# CONTROLSS_GLOBAL_CTRL_CONTROLSS_CTRL_502F0000h register map
Vendor: Texas Instruments
Peripheral module from a debugger description file (folder AM263X).
Registers are 32-bit, read-write, reset 0x0 unless marked. A register's access mark holds for its fields unless they carry their own. Offsets are as the file gives them; lines under a group give offsets from that group; [hi:lo] are bit positions; {n}, {i} and the like mark numbered series; 'fields as' and 'values as' point back to an identical list; <NAME> marks a mode.

## CONTROLSS_CTRL
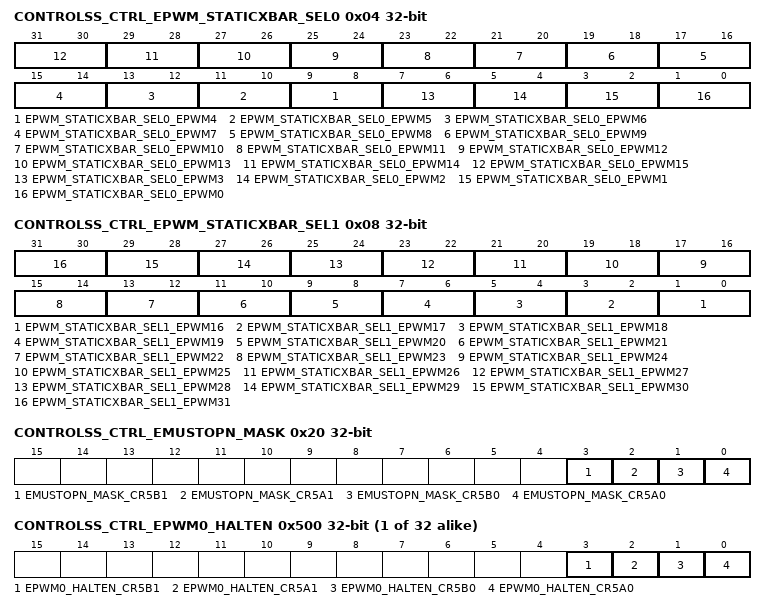
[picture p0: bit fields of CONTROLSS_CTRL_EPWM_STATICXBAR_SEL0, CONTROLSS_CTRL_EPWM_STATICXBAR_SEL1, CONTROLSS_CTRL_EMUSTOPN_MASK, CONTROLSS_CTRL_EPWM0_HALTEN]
0x04 CONTROLSS_CTRL_EPWM_STATICXBAR_SEL0 — Static crossbar for epwm select.
  [2n+1:2n] EPWM_STATICXBAR_SEL0_EPWM{n} (n=4..15) — EPWM{n} access from PCR grouping. Write the following value to access groups - - 2'b00 = G0, 2'b01 =G1, 2'b10 =G2, 2'b11 =G3
  [7:6] EPWM_STATICXBAR_SEL0_EPWM3 — EPWM3 access from PCR grouping. Write the following value to access groups - 2'b00 = G0, 2'b01 =G1, 2'b10 =G2, 2'b11 =G3
  [5:4] EPWM_STATICXBAR_SEL0_EPWM2 — EPWM2 access from PCR grouping. Write the following value to access groups - - 2'b00 = G0, 2'b01 =G1, 2'b10 =G2, 2'b11 =G3
  [3:2] EPWM_STATICXBAR_SEL0_EPWM1 — EPWM1 access from PCR grouping. Write the following value to access groups - - 2'b00 = G0, 2'b01 =G1, 2'b10 =G2, 2'b11 =G3
  [1:0] EPWM_STATICXBAR_SEL0_EPWM0 — EPWM0 access from PCR grouping. Write the following value to access groups - - 2'b00 = G0, 2'b01 =G1, 2'b10 =G2, 2'b11 =G3
0x08 CONTROLSS_CTRL_EPWM_STATICXBAR_SEL1 — Static crossbar for epwm select.
  [2n-31:2n-32] EPWM_STATICXBAR_SEL1_EPWM{n} (n=16..31) — EPWM{n} access from PCR grouping. Write the following value to access groups - - 2'b00 = G0, 2'b01 =G1, 2'b10 =G2, 2'b11 =G3
0x10 CONTROLSS_CTRL_EPWM_CLKSYNC — Epwm clock sync.
  [31:0] EPWM_CLKSYNC_BIT — EPWM clock sync for each EPWM instance. Set the bit corresponding to the instance number to enable that EPWM instance. When set, all enabled EPWM module clocks are started with the first rising edge of TBCLK aligned.Refer to TRM for more details.Writing 1'b1 will allow to enable corresponding EPWM instanceWriting 1'b0 will disable corresponding EPWM instance.
0x18 CONTROLSS_CTRL_SDFM1_CLK0_SEL — Sdfm1 clock select.
  [0] SDFM1_CLK0_SEL_SEL — SDFM1 clock CK0 selectWrite 1'b0: source is SDFM1 CK0 from PinmuxWrite 1'b1: source is SDFM0 CK0 from Pinmux
0x20 CONTROLSS_CTRL_EMUSTOPN_MASK — Bit-mask for debug suspend cpu cores to EPWM.
  [3] EMUSTOPN_MASK_CR5B1 — Bit-mask for debug suspend cpu cores to EPWM1'b0 : R5FSS1_CORE1 enabled to control EMUSTOPn1'b1 : R5FSS1_CORE1 disabled to control EMUSTOPn
  [2] EMUSTOPN_MASK_CR5A1 — Bit-mask for debug suspend cpu cores to EPWM1'b0 : R5FSS1_CORE0 enabled to control EMUSTOPn1'b1 : R5FSS1_CORE0 disabled to control EMUSTOPn
  [1] EMUSTOPN_MASK_CR5B0 — Bit-mask for debug suspend cpu cores to EPWM1'b0 : R5FSS0_CORE1 enabled to control EMUSTOPn1'b1 : R5FSS0_CORE1 disabled to control EMUSTOPn
  [0] EMUSTOPN_MASK_CR5A0 — Bit-mask for debug suspend cpu cores to EPWM1'b0 : R5FSS0_CORE0 enabled to control EMUSTOPn1'b1 : R5FSS0_CORE0 disabled to control EMUSTOPn
0x28 CONTROLSS_CTRL_CLB_AQ_EN0 — clb_aq_en0.
  [31:0] CLB_AQ_EN0_ENABLE — Enable ICCS control to CLB_AQ signal of PWM[15:0]. Set Bitx to 1'b1 to enable it for PWMx. Here x varies from 0-15.
0x30 CONTROLSS_CTRL_CLB_AQ_EN1 — clb_aq_en1.
  [31:0] CLB_AQ_EN1_ENABLE — Enable ICCS control to CLB_AQ signal of PWM[31:16].Set Bitx to 1'b1 to enable it for PWMx. Here x varies from 16-31.
0x38 CONTROLSS_CTRL_CLB_DB_EN0 — clb_db_en0.
  [31:0] CLB_DB_EN0_ENABLE — Enable ICCS control to CLB_DB signal of PWM[15:0]. Set Bitx to 1'b1 to enable it for PWMx. Here x varies from 0-15.
0x40 CONTROLSS_CTRL_CLB_DB_EN1 — clb_db_en1.
  [31:0] CLB_DB_EN1_ENABLE — Enable ICCS control to CLB_DB signal of PWM[31:16].Set Bitx to 1'b1 to enable it for PWMx. Here x varies from 16-31.
{0x100+4i} CONTROLSS_CTRL_EPWM{i}_CLK_GATE (i=0..31) — To clock gate epwm[x].
  [2:0] EPWM{i}_CLK_GATE_CLK_GATE — Writing 3'b111 will gate clock for corresponding epwm
{0x180+4i} CONTROLSS_CTRL_FSI_TX{i}_CLK_GATE (i=0..3) — fsi_tx[x] clock gate.
  [2:0] FSI_TX{i}_CLK_GATE_CLK_GATE — Writing 3'b111 will gate clock for corresponding fsi_tx
{0x190+4i} CONTROLSS_CTRL_FSI_RX{i}_CLK_GATE (i=0..3) — fsi_rx[x] clock gate.
  [2:0] FSI_RX{i}_CLK_GATE_CLK_GATE — Writing 3'b111 will gate clock for corresponding fsi_rx
{0x1A0+4i} CONTROLSS_CTRL_CMPSSA{i}_CLK_GATE (i=0..9) — cmpssa[x] clock gate.
  [2:0] CMPSSA{i}_CLK_GATE_CLK_GATE — Writing 3'b111 will gate clock for corresponding cmpssa
{0x1D0+4i} CONTROLSS_CTRL_CMPSSB{i}_CLK_GATE (i=0..9) — cmpssb[x] clock gate.
  [2:0] CMPSSB{i}_CLK_GATE_CLK_GATE — Writing 3'b111 will gate clock for corresponding cmpssb
{0x200+4i} CONTROLSS_CTRL_ECAP{i}_CLK_GATE (i=0..9) — Ecap[x] clock gate.
  [2:0] ECAP{i}_CLK_GATE_CLK_GATE — Writing 3'b111 will gate clock for corresponding ecap
{0x240+4i} CONTROLSS_CTRL_EQEP{i}_CLK_GATE (i=0..2) — Eqep[x] clock gate.
  [2:0] EQEP{i}_CLK_GATE_CLK_GATE — Writing 3'b111 will gate clock for corresponding eqep
0x250 CONTROLSS_CTRL_SDFM0_CLK_GATE — Sdfm[x] clock gate.
  [2:0] SDFM0_CLK_GATE_CLK_GATE — Writing 3'b111 will gate clock for corresponding sdfm
0x254 CONTROLSS_CTRL_SDFM1_CLK_GATE — Sdfm[x] clock gate.
  [2:0] SDFM1_CLK_GATE_CLK_GATE — Writing 3'b111 will gate clock for corresponding sdfm
0x258 CONTROLSS_CTRL_DAC_CLK_GATE — dac clock gate.
  [2:0] DAC_CLK_GATE_CLK_GATE — Writing 3'b111 will gate clock for dac
{0x25C+4i} CONTROLSS_CTRL_ADC{i}_CLK_GATE (i=0..4) — Adc[x] clock gate.
  [2:0] ADC{i}_CLK_GATE_CLK_GATE — Writing 3'b111 will gate clock for corresponding adc
{0x270+4i} CONTROLSS_CTRL_OTTO{i}_CLK_GATE (i=0..3) — Otto[x] clock gate.
  [2:0] OTTO{i}_CLK_GATE_CLK_GATE — Writing 3'b111 will gate clock for corresponding otto
0x280 CONTROLSS_CTRL_SDFM0_PLL_CLK_GATE — Sdfm[x]_pll clock gate.
  [2:0] SDFM0_PLL_CLK_GATE_CLK_GATE — Writing 3'b111 will gate clock for corresponding sdfm pll clock
0x284 CONTROLSS_CTRL_SDFM1_PLL_CLK_GATE — Sdfm[x]_pll clock gate.
  [2:0] SDFM1_PLL_CLK_GATE_CLK_GATE — Writing 3'b111 will gate clock for corresponding sdfm pll clock
{0x288+4i} CONTROLSS_CTRL_FSI_TX{i}_PLL_CLK_GATE (i=0..3) — fsi_tx[x]_pll clock gate.
  [2:0] FSI_TX{i}_PLL_CLK_GATE_CLK_GATE — Writing 3'b111 will gate clock for corresponding fsi rx pll clock
{0x300+4i} CONTROLSS_CTRL_EPWM{i}_RST (i=0..31) — Epwm[x]_reset.
  [2:0] EPWM{i}_RST_RST — Writing 3'b111 will generate reset for corresponding epwm
{0x380+4i} CONTROLSS_CTRL_FSI_TX{i}_RST (i=0..3) — fsi_tx[x]_reset.
  [2:0] FSI_TX{i}_RST_RST — Writing 3'b111 will generate reset for corresponding fsi_tx
{0x390+4i} CONTROLSS_CTRL_FSI_RX{i}_RST (i=0..3) — fsi_rx[x]_reset.
  [2:0] FSI_RX{i}_RST_RST — Writing 3'b111 will generate reset for corresponding fsi_rx
{0x3A0+4i} CONTROLSS_CTRL_CMPSSA{i}_RST (i=0..9) — cmpssa[x]_reset.
  [2:0] CMPSSA{i}_RST_RST — Writing 3'b111 will generate reset for corresponding cmpssa
{0x3D0+4i} CONTROLSS_CTRL_CMPSSB{i}_RST (i=0..9) — cmpssb[x]_reset.
  [2:0] CMPSSB{i}_RST_RST — Writing 3'b111 will generate reset for corresponding cmpssb
{0x400+4i} CONTROLSS_CTRL_ECAP{i}_RST (i=0..9) — Ecap[x]_reset.
  [2:0] ECAP{i}_RST_RST — Writing 3'b111 will generate reset for corresponding ecap
{0x440+4i} CONTROLSS_CTRL_EQEP{i}_RST (i=0..2) — Eqep[x]_reset.
  [2:0] EQEP{i}_RST_RST — Writing 3'b111 will generate reset for corresponding eqep
0x450 CONTROLSS_CTRL_SDFM0_RST — Sdfm[x]_reset.
  [2:0] SDFM0_RST_RST — Writing 3'b111 will generate reset for corresponding sdfm
0x454 CONTROLSS_CTRL_SDFM1_RST — Sdfm[x]_reset.
  [2:0] SDFM1_RST_RST — Writing 3'b111 will generate reset for corresponding sdfm
0x458 CONTROLSS_CTRL_DAC_RST — dac_reset.
  [2:0] DAC_RST_RST — Writing 3'b111 will generate reset for dac
{0x45C+4i} CONTROLSS_CTRL_ADC{i}_RST (i=0..4) — Adc[x]_reset.
  [2:0] ADC{i}_RST_RST — Writing 3'b111 will generate reset for corresponding adc
{0x470+4i} CONTROLSS_CTRL_OTTO{i}_RST (i=0..3) — Otto[x]_reset.
  [2:0] OTTO{i}_RST_RST — Writing 3'b111 will generate reset for corresponding otto
{0x500+4i} CONTROLSS_CTRL_EPWM{i}_HALTEN (i=0..31) — Epwm halt enable.
  [3] EPWM{i}_HALTEN_CR5B1 — Write 1'b0: IP Halt disabled with corresponding CPU haltWrite 1'b1: IP Halt enabled with corresponding CPU halt
  [2] EPWM{i}_HALTEN_CR5A1 — Write 1'b0: IP Halt disabled with corresponding CPU haltWrite 1'b1: IP Halt enabled with corresponding CPU halt
  [1] EPWM{i}_HALTEN_CR5B0 — Write 1'b0: IP Halt disabled with corresponding CPU haltWrite 1'b1: IP Halt enabled with corresponding CPU halt
  [0] EPWM{i}_HALTEN_CR5A0 — Write 1'b0: IP Halt disabled with corresponding CPU haltWrite 1'b1: IP Halt enabled with corresponding CPU halt
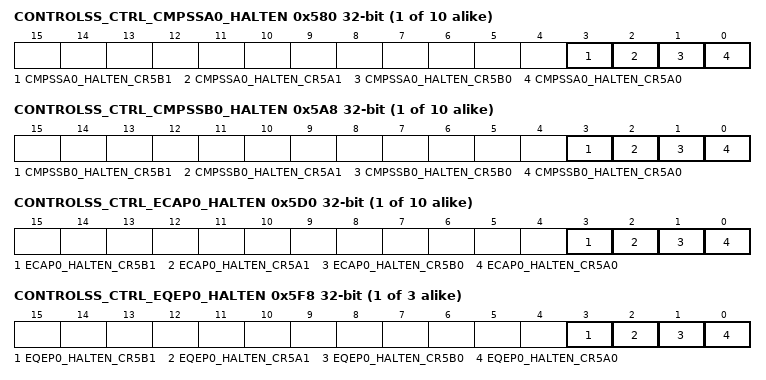
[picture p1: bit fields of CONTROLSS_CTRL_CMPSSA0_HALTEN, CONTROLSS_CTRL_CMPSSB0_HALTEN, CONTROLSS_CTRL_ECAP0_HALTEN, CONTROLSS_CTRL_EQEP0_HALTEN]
{0x580+4i} CONTROLSS_CTRL_CMPSSA{i}_HALTEN (i=0..9) — cmpssa halt enable.
  [3] CMPSSA{i}_HALTEN_CR5B1 — Write 1'b0: IP Halt disabled with corresponding CPU haltWrite 1'b1: IP Halt enabled with corresponding CPU halt
  [2] CMPSSA{i}_HALTEN_CR5A1 — Write 1'b0: IP Halt disabled with corresponding CPU haltWrite 1'b1: IP Halt enabled with corresponding CPU halt
  [1] CMPSSA{i}_HALTEN_CR5B0 — Write 1'b0: IP Halt disabled with corresponding CPU haltWrite 1'b1: IP Halt enabled with corresponding CPU halt
  [0] CMPSSA{i}_HALTEN_CR5A0 — Write 1'b0: IP Halt disabled with corresponding CPU haltWrite 1'b1: IP Halt enabled with corresponding CPU halt
{0x5A8+4i} CONTROLSS_CTRL_CMPSSB{i}_HALTEN (i=0..9) — cmpssb halt enable.
  [3] CMPSSB{i}_HALTEN_CR5B1 — Write 1'b0: IP Halt disabled with corresponding CPU haltWrite 1'b1: IP Halt enabled with corresponding CPU halt
  [2] CMPSSB{i}_HALTEN_CR5A1 — Write 1'b0: IP Halt disabled with corresponding CPU haltWrite 1'b1: IP Halt enabled with corresponding CPU halt
  [1] CMPSSB{i}_HALTEN_CR5B0 — Write 1'b0: IP Halt disabled with corresponding CPU haltWrite 1'b1: IP Halt enabled with corresponding CPU halt
  [0] CMPSSB{i}_HALTEN_CR5A0 — Write 1'b0: IP Halt disabled with corresponding CPU haltWrite 1'b1: IP Halt enabled with corresponding CPU halt
{0x5D0+4i} CONTROLSS_CTRL_ECAP{i}_HALTEN (i=0..9) — Ecap halt enable.
  [3] ECAP{i}_HALTEN_CR5B1 — Write 1'b0: IP Halt disabled with corresponding CPU haltWrite 1'b1: IP Halt enabled with corresponding CPU halt
  [2] ECAP{i}_HALTEN_CR5A1 — Write 1'b0: IP Halt disabled with corresponding CPU haltWrite 1'b1: IP Halt enabled with corresponding CPU halt
  [1] ECAP{i}_HALTEN_CR5B0 — Write 1'b0: IP Halt disabled with corresponding CPU haltWrite 1'b1: IP Halt enabled with corresponding CPU halt
  [0] ECAP{i}_HALTEN_CR5A0 — Write 1'b0: IP Halt disabled with corresponding CPU haltWrite 1'b1: IP Halt enabled with corresponding CPU halt
{0x5F8+4i} CONTROLSS_CTRL_EQEP{i}_HALTEN (i=0..2) — Eqep halt enable.
  [3] EQEP{i}_HALTEN_CR5B1 — Write 1'b0: IP Halt disabled with corresponding CPU haltWrite 1'b1: IP Halt enabled with corresponding CPU halt
  [2] EQEP{i}_HALTEN_CR5A1 — Write 1'b0: IP Halt disabled with corresponding CPU haltWrite 1'b1: IP Halt enabled with corresponding CPU halt
  [1] EQEP{i}_HALTEN_CR5B0 — Write 1'b0: IP Halt disabled with corresponding CPU haltWrite 1'b1: IP Halt enabled with corresponding CPU halt
  [0] EQEP{i}_HALTEN_CR5A0 — Write 1'b0: IP Halt disabled with corresponding CPU haltWrite 1'b1: IP Halt enabled with corresponding CPU halt
0x1008 CONTROLSS_CTRL_LOCK0_KICK0 — - KICK0 component.
  [31:0] LOCK0_KICK0 — - KICK0 component
0x100C CONTROLSS_CTRL_LOCK0_KICK1 — - KICK1 component.
  [31:0] LOCK0_KICK1 — - KICK1 component
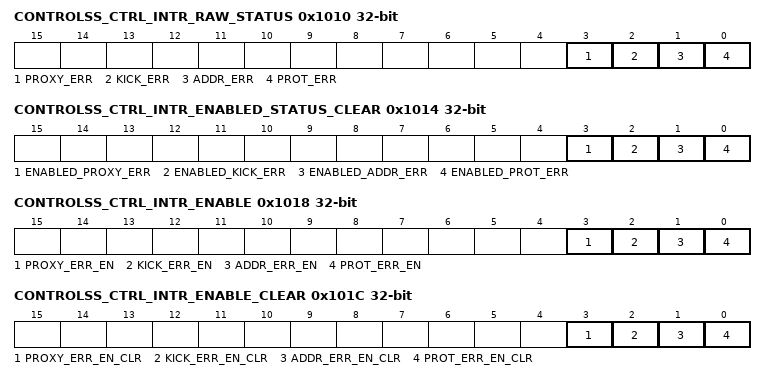
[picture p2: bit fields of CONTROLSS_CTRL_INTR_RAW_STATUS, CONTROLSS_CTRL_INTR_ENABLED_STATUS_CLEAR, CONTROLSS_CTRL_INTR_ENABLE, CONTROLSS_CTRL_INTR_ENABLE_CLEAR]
0x1010 CONTROLSS_CTRL_INTR_RAW_STATUS access not given — Interrupt Raw Status/Set Register.
  [3] PROXY_ERR — Proxy0 access violation error. Raw status is read. Write a 1 to set the status. Writing a 0 has no effect. (access R/W1TS)
  [2] KICK_ERR — Kick access violation error. Raw status is read. Write a 1 to set the status. Writing a 0 has no effect. (access R/W1TS)
  [1] ADDR_ERR — Addressing violation error. Raw status is read. Write a 1 to set the status. Writing a 0 has no effect. (access R/W1TS)
  [0] PROT_ERR — Protection violation error. Raw status is read. Write a 1 to set the status. Writing a 0 has no effect. (access R/W1TS)
0x1014 CONTROLSS_CTRL_INTR_ENABLED_STATUS_CLEAR access not given — Interrupt Enabled Status/Clear register.
  [3] ENABLED_PROXY_ERR — Proxy0 access violation error. Enabled status is read. Write a 1 to clear the status. Writing a 0 has no effect. (access R/W1TC)
  [2] ENABLED_KICK_ERR — Kick access violation error. Enabled status is read. Write a 1 to clear the status. Writing a 0 has no effect. (access R/W1TC)
  [1] ENABLED_ADDR_ERR — Addressing violation error. Enabled status is read. Write a 1 to clear the status. Writing a 0 has no effect. (access R/W1TC)
  [0] ENABLED_PROT_ERR — Protection violation error. Enabled status is read. Write a 1 to clear the status. Writing a 0 has no effect. (access R/W1TC)
0x1018 CONTROLSS_CTRL_INTR_ENABLE access not given — Interrupt Enable register.
  [3] PROXY_ERR_EN — Proxy0 access violation error enable. Write a 1 to set the enable. Writing a 0 has no effect. (access R/W1TS)
  [2] KICK_ERR_EN — Kick access violation error enable. Write a 1 to set the enable. Writing a 0 has no effect. (access R/W1TS)
  [1] ADDR_ERR_EN — Addressing violation error enable. Write a 1 to set the enable. Writing a 0 has no effect. (access R/W1TS)
  [0] PROT_ERR_EN — Protection violation error enable. Write a 1 to set the enable. Writing a 0 has no effect. (access R/W1TS)
0x101C CONTROLSS_CTRL_INTR_ENABLE_CLEAR access not given — Interrupt Enable Clear register.
  [3] PROXY_ERR_EN_CLR — Proxy0 access violation error enable clear. Write a 1 to clear the enable. Writing a 0 has no effect. (access R/W1TC)
  [2] KICK_ERR_EN_CLR — Kick access violation error enable clear. Write a 1 to clear the enable. Writing a 0 has no effect. (access R/W1TC)
  [1] ADDR_ERR_EN_CLR — Addressing violation error enable clear. Write a 1 to clear the enable. Writing a 0 has no effect. (access R/W1TC)
  [0] PROT_ERR_EN_CLR — Protection violation error enable clear. Write a 1 to clear the enable. Writing a 0 has no effect. (access R/W1TC)
0x1020 CONTROLSS_CTRL_EOI — EOI register.
  [7:0] EOI_VECTOR — EOI vector value. Write this with interrupt distribution value in the chip.
0x1024 CONTROLSS_CTRL_FAULT_ADDRESS ro — Fault Address register.
  [31:0] FAULT_ADDR — Fault Address.
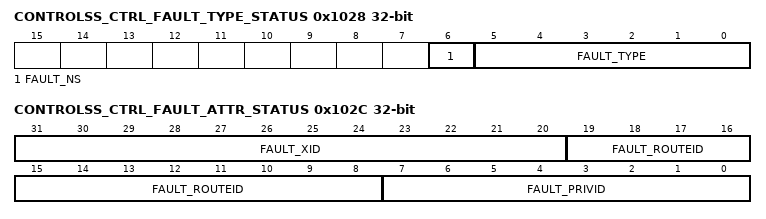
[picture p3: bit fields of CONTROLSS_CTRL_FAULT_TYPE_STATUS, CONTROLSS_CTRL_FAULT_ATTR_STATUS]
0x1028 CONTROLSS_CTRL_FAULT_TYPE_STATUS ro — Fault Type Status register.
  [6] FAULT_NS — Non-secure access.
  [5:0] FAULT_TYPE — Fault Type 10_0000 = Supervisor read fault - priv = 1 dir = 1 dtype != 1 01_0000 = Supervisor write fault - priv = 1 dir = 0 00_1000 = Supervisor execute fault - priv = 1 dir = 1 dtype = 1 00_0100 = User read fault - priv = 0 dir = 1 dtype = 1 00_0010 = User write fault - priv = 0 dir = 0 00_0001 = User execute fault - priv = 0 dir = 1 dtype = 1 00_0000 = No fault
0x102C CONTROLSS_CTRL_FAULT_ATTR_STATUS ro — Fault Attribute Status register.
  [31:20] FAULT_XID — XID.
  [19:8] FAULT_ROUTEID — Route ID.
  [7:0] FAULT_PRIVID — Privilege ID.
0x1030 CONTROLSS_CTRL_FAULT_CLEAR wo — Fault Clear register.
  [0] FAULT_CLR — Fault clear. Writing a 1 clears the current fault. Writing a 0 has no effect.
